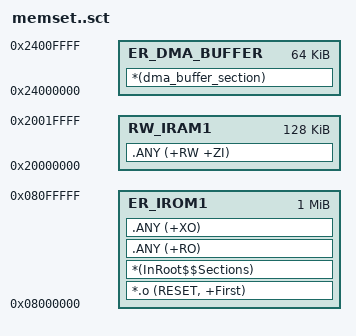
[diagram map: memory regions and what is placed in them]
;————— 1. Flash + ?? RAM(????) —————
LR_IROM1 0x08000000 0x00100000  {    ; load region = Flash 1 MB
  ER_IROM1 0x08000000 0x00100000  {  ; execute region = Flash 1 MB
    *.o (RESET, +First)
    *(InRoot$$Sections)
    .ANY (+RO)
    .ANY (+XO)
  }
  RW_IRAM1 0x20000000 0x00020000  {  ; DTCM/CCM/?? SRAM(128 KB)
    .ANY (+RW +ZI)
  }
}

;————— 2. AHB SRAM1 (AXI-SRAM1) ??? DMA —————
LR_SRAM1 0x24000000 0x00080000  {    ; AHB SRAM1 ??? 512 KB
  ; —— 2.1 DMA Buffer ?? —— 
  ER_DMA_BUFFER 0x24000000 0x00010000  {  ; 64 KB ?? DMA
    *(dma_buffer_section)                   ; ???? __attribute__ ??? section
  }
  ; —— 2.2 SRAM1 ???? —— 
 
}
